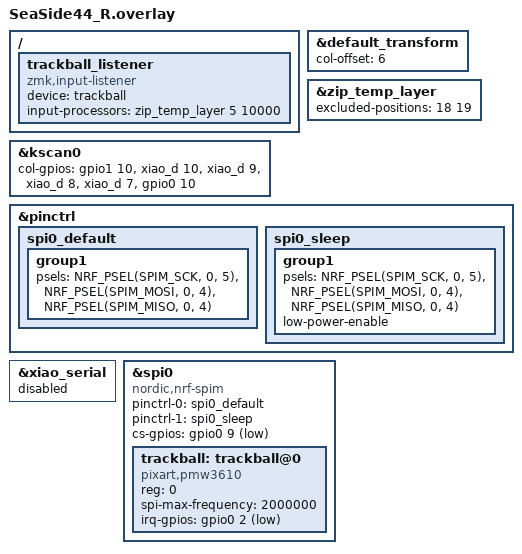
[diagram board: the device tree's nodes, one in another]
#include "SeaSide44.dtsi"
#include <input/processors.dtsi> // ファイルの先頭付近に記述

&default_transform {
    col-offset = <6>;
};

/* キーマトリクスの設定 */
&kscan0 {
    col-gpios
        = <&gpio1 10 GPIO_ACTIVE_HIGH>
        , <&xiao_d 10 GPIO_ACTIVE_HIGH>
        , <&xiao_d 9 GPIO_ACTIVE_HIGH> 
        , <&xiao_d 8 GPIO_ACTIVE_HIGH> 
        , <&xiao_d 7 GPIO_ACTIVE_HIGH> 
        , <&gpio0 10 GPIO_ACTIVE_HIGH>
        ;
};

/* トラックボールのリスナー設定 (統合版) */
/ {
    trackball_listener: trackball_listener {
        compatible = "zmk,input-listener";
        device = <&trackball>;

        /* トラックボール操作でレイヤー5を有効化 (タイムアウト10000ms) */
        input-processors = <&zip_temp_layer 5 10000>;
    };
};

/* Input Processor の詳細設定 */
&zip_temp_layer {
    /* 除外したいキーのポジションを指定 */
    excluded-positions = <
        18 // 例: Jキー
        19 // 例: Kキー
    >;
};

/* SPI 設定 (既存のまま) */
&pinctrl {
    spi0_default: spi0_default {
        group1 {
            psels = <NRF_PSEL(SPIM_SCK, 0, 5)>,
                <NRF_PSEL(SPIM_MOSI, 0, 4)>,
                <NRF_PSEL(SPIM_MISO, 0, 4)>;
        };
    };

    spi0_sleep: spi0_sleep {
        group1 {
            psels = <NRF_PSEL(SPIM_SCK, 0, 5)>,
                <NRF_PSEL(SPIM_MOSI, 0, 4)>,
                <NRF_PSEL(SPIM_MISO, 0, 4)>;
            low-power-enable;
        };
    };
};

&xiao_serial { status = "disabled"; };

&spi0 {
    status = "okay";
    compatible = "nordic,nrf-spim";
    pinctrl-0 = <&spi0_default>;
    pinctrl-1 = <&spi0_sleep>;
    pinctrl-names = "default", "sleep";
    cs-gpios = <&gpio0 9 GPIO_ACTIVE_LOW>;

    trackball: trackball@0 {
        status = "okay";
        compatible = "pixart,pmw3610";
        reg = <0>;
        spi-max-frequency = <2000000>;
        irq-gpios = <&gpio0 2 (GPIO_ACTIVE_LOW | GPIO_PULL_UP)>;
        
        /* 注意: 下記を有効にすると ZIP の設定と競合する可能性があるため、*/
        /* 新しい input-processors 方式を使う場合はコメントアウトを推奨します。 */
        // scroll-layers = <5>; 
    };
};
